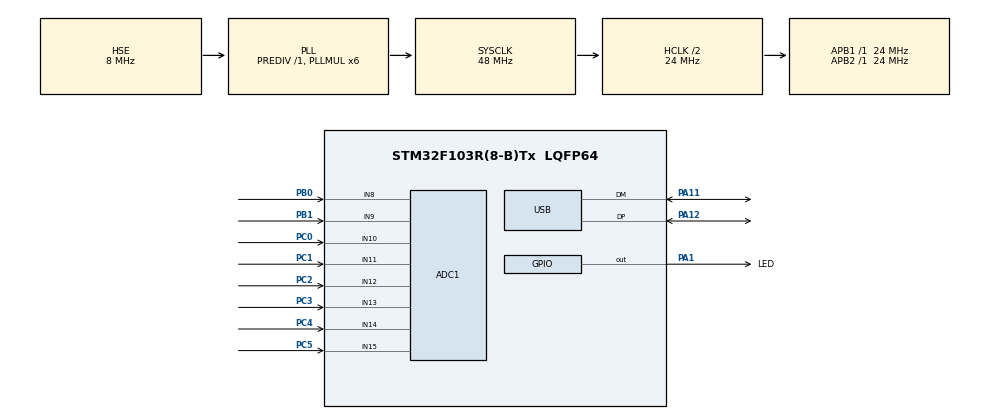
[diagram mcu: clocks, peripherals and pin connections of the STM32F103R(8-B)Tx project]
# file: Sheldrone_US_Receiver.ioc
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ADC1.Channel-0\#ChannelRegularConversion=ADC_CHANNEL_8
ADC1.Channel-1\#ChannelRegularConversion=ADC_CHANNEL_9
ADC1.Channel-2\#ChannelRegularConversion=ADC_CHANNEL_10
ADC1.Channel-3\#ChannelRegularConversion=ADC_CHANNEL_11
ADC1.Channel-4\#ChannelRegularConversion=ADC_CHANNEL_12
ADC1.Channel-5\#ChannelRegularConversion=ADC_CHANNEL_13
ADC1.Channel-6\#ChannelRegularConversion=ADC_CHANNEL_14
ADC1.Channel-7\#ChannelRegularConversion=ADC_CHANNEL_15
ADC1.ContinuousConvMode=ENABLE
ADC1.InjNumberOfConversion=0
ADC1.NbrOfConversion=8
ADC1.NbrOfConversionFlag=1
ADC1.Rank-0\#ChannelRegularConversion=1
ADC1.Rank-1\#ChannelRegularConversion=2
ADC1.Rank-2\#ChannelRegularConversion=3
ADC1.Rank-3\#ChannelRegularConversion=4
ADC1.Rank-4\#ChannelRegularConversion=5
ADC1.Rank-5\#ChannelRegularConversion=6
ADC1.Rank-6\#ChannelRegularConversion=7
ADC1.Rank-7\#ChannelRegularConversion=8
ADC1.SamplingTime-0\#ChannelRegularConversion=ADC_SAMPLETIME_1CYCLE_5
ADC1.SamplingTime-1\#ChannelRegularConversion=ADC_SAMPLETIME_1CYCLE_5
ADC1.SamplingTime-2\#ChannelRegularConversion=ADC_SAMPLETIME_1CYCLE_5
ADC1.SamplingTime-3\#ChannelRegularConversion=ADC_SAMPLETIME_1CYCLE_5
ADC1.SamplingTime-4\#ChannelRegularConversion=ADC_SAMPLETIME_1CYCLE_5
ADC1.SamplingTime-5\#ChannelRegularConversion=ADC_SAMPLETIME_1CYCLE_5
ADC1.SamplingTime-6\#ChannelRegularConversion=ADC_SAMPLETIME_1CYCLE_5
ADC1.SamplingTime-7\#ChannelRegularConversion=ADC_SAMPLETIME_1CYCLE_5
ADC1.master=1
Dma.ADC1.0.Direction=DMA_PERIPH_TO_MEMORY
Dma.ADC1.0.Instance=DMA1_Channel1
Dma.ADC1.0.MemDataAlignment=DMA_MDATAALIGN_HALFWORD
Dma.ADC1.0.MemInc=DMA_MINC_ENABLE
Dma.ADC1.0.Mode=DMA_CIRCULAR
Dma.ADC1.0.PeriphDataAlignment=DMA_PDATAALIGN_HALFWORD
Dma.ADC1.0.PeriphInc=DMA_PINC_DISABLE
Dma.ADC1.0.Priority=DMA_PRIORITY_MEDIUM
Dma.Request0=ADC1
Mcu.Family=STM32F1
Mcu.Name=STM32F103R(8-B)Tx
Mcu.Package=LQFP64
NVIC.DMA1_Channel1_IRQn=true\:0\:0\:false
NVIC.PriorityGroup=NVIC_PRIORITYGROUP_4
NVIC.USB_LP_CAN1_RX0_IRQn=true\:0\:0\:false
PA1.GPIO_Label=LED
PA1.Signal=GPIO_Output
PA11.Mode=Device
PA11.Signal=USB_DM
PA12.Mode=Device
PA12.Signal=USB_DP
PB0.Signal=ADCx_IN8
PB1.Signal=ADCx_IN9
PC0.Signal=ADCx_IN10
PC1.Signal=ADCx_IN11
PC14-OSC32_IN.Mode=LSE-External-Oscillator
PC14-OSC32_IN.Signal=RCC_OSC32_IN
PC15-OSC32_OUT.Mode=LSE-External-Oscillator
PC15-OSC32_OUT.Signal=RCC_OSC32_OUT
PC2.Signal=ADCx_IN12
PC3.Signal=ADCx_IN13
PC4.Signal=ADCx_IN14
PC5.Signal=ADCx_IN15
PD0-OSC_IN.Mode=HSE-External-Oscillator
PD0-OSC_IN.Signal=RCC_OSC_IN
PD1-OSC_OUT.Mode=HSE-External-Oscillator
PD1-OSC_OUT.Signal=RCC_OSC_OUT
ProjectManager.TargetToolchain=MDK-ARM V5
RCC.AHBCLKDivider=RCC_SYSCLK_DIV2
RCC.AHBFreq_Value=24000000
RCC.APB1Freq_Value=24000000
RCC.APB1TimFreq_Value=24000000
RCC.APB2Freq_Value=24000000
RCC.APB2TimFreq_Value=24000000
RCC.HCLKFreq_Value=24000000
RCC.HSIState=RCC_HSI_ON
RCC.PLLMUL=RCC_PLL_MUL6
RCC.SYSCLKFreq_VALUE=48000000
RCC.SYSCLKSource=RCC_SYSCLKSOURCE_PLLCLK
RCC.USBFreq_Value=48000000
SH.ADCx_IN10.0=ADC1_IN10,IN10
SH.ADCx_IN11.0=ADC1_IN11,IN11
SH.ADCx_IN12.0=ADC1_IN12,IN12
SH.ADCx_IN13.0=ADC1_IN13,IN13
SH.ADCx_IN14.0=ADC1_IN14,IN14
SH.ADCx_IN15.0=ADC1_IN15,IN15
SH.ADCx_IN8.0=ADC1_IN8,IN8
SH.ADCx_IN9.0=ADC1_IN9,IN9
USB_DEVICE.USBD_HandleTypeDef=hUsbDeviceFS
USB_DEVICE.VirtualMode=Cdc
USB_DEVICE.VirtualModeFS=Cdc_FS
VP_USB_DEVICE_VS_USB_DEVICE_CDC_FS.Mode=CDC_FS
board=Sheldrone_US_Receiver

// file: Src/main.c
/**
  ******************************************************************************
  * File Name          : main.c
  * Description        : Main program body
  ******************************************************************************
  *
  * COPYRIGHT(c) 2015 STMicroelectronics
  *
  * Redistribution and use in source and binary forms, with or without modification,
  * are permitted provided that the following conditions are met:
  *   1. Redistributions of source code must retain the above copyright notice,
  *      this list of conditions and the following disclaimer.
  *   2. Redistributions in binary form must reproduce the above copyright notice,
  *      this list of conditions and the following disclaimer in the documentation
  *      and/or other materials provided with the distribution.
  *   3. Neither the name of STMicroelectronics nor the names of its contributors
  *      may be used to endorse or promote products derived from this software
  *      without specific prior written permission.
  *
  * THIS SOFTWARE IS PROVIDED BY THE COPYRIGHT HOLDERS AND CONTRIBUTORS "AS IS"
  * AND ANY EXPRESS OR IMPLIED WARRANTIES, INCLUDING, BUT NOT LIMITED TO, THE
  * IMPLIED WARRANTIES OF MERCHANTABILITY AND FITNESS FOR A PARTICULAR PURPOSE ARE
  * DISCLAIMED. IN NO EVENT SHALL THE COPYRIGHT HOLDER OR CONTRIBUTORS BE LIABLE
  * FOR ANY DIRECT, INDIRECT, INCIDENTAL, SPECIAL, EXEMPLARY, OR CONSEQUENTIAL
  * DAMAGES (INCLUDING, BUT NOT LIMITED TO, PROCUREMENT OF SUBSTITUTE GOODS OR
  * SERVICES; LOSS OF USE, DATA, OR PROFITS; OR BUSINESS INTERRUPTION) HOWEVER
  * CAUSED AND ON ANY THEORY OF LIABILITY, WHETHER IN CONTRACT, STRICT LIABILITY,
  * OR TORT (INCLUDING NEGLIGENCE OR OTHERWISE) ARISING IN ANY WAY OUT OF THE USE
  * OF THIS SOFTWARE, EVEN IF ADVISED OF THE POSSIBILITY OF SUCH DAMAGE.
  *
  ******************************************************************************
  */
#include "stm32f1xx_hal.h"
#include "usb_device.h"
#include "usbd_cdc_if.h"

/* USER CODE BEGIN Includes */
#include "customUtils.h"
/* USER CODE END Includes */

ADC_HandleTypeDef hadc1;
DMA_HandleTypeDef hdma_adc1;

/* USER CODE BEGIN PV */
/* Private variables ---------------------------------------------------------*/

/* USER CODE END PV */

void SystemClock_Config(void);
static void MX_GPIO_Init(void);
static void MX_DMA_Init(void);
static void MX_ADC1_Init(void);

/* USER CODE BEGIN PFP */
/* Private function prototypes -----------------------------------------------*/

/* USER CODE END PFP */

/* USER CODE BEGIN 0 */

/// Array to store ADC data
#define ADC1_DATA_ARRAY_SIZE	1024
uint32_t ADC1ConvertedValues[ADC1_DATA_ARRAY_SIZE];

/* USER CODE END 0 */

int main(void)
{

  /* MCU Configuration----------------------------------------------------------*/

  /* Reset of all peripherals, Initializes the Flash interface and the Systick. */
  HAL_Init();

  /* Configure the system clock */
  SystemClock_Config();

  /* Initialize all configured peripherals */
  MX_GPIO_Init();
  MX_DMA_Init();
  MX_ADC1_Init();
  MX_USB_DEVICE_Init();

  /* USER CODE BEGIN 2 */

	// -- Enables ADC and starts conversion of the regular channels.
  if( HAL_ADC_Start(&hadc1) != HAL_OK)
		return 0;
  // -- Enables ADC DMA request
  if (HAL_ADC_Start_DMA(&hadc1, (uint32_t*)ADC1ConvertedValues, ADC1_DATA_ARRAY_SIZE*2) != HAL_OK)
		return 0;

  /* USER CODE END 2 */

  /* Infinite loop */
  /* USER CODE BEGIN WHILE */

	uint8_t dataToSend[11] = "Hello World";

	// Wait for USB to be ready
	//while(!Is_CDC_Ready());
	//HAL_Delay(1000);

  while (1)
  {
		//CDC_Transmit_FS(dataToSend, 11); // Length < APP_TX_DATA_SIZE
		//HAL_Delay(1000);

  /* USER CODE END WHILE */

  }

}

/** System Clock Configuration
*/
void SystemClock_Config(void)
{

  RCC_OscInitTypeDef RCC_OscInitStruct;
  RCC_ClkInitTypeDef RCC_ClkInitStruct;
  RCC_PeriphCLKInitTypeDef PeriphClkInit;

  RCC_OscInitStruct.OscillatorType = RCC_OSCILLATORTYPE_HSE;
  RCC_OscInitStruct.HSEState = RCC_HSE_ON;
  RCC_OscInitStruct.HSEPredivValue = RCC_HSE_PREDIV_DIV1;
  RCC_OscInitStruct.PLL.PLLState = RCC_PLL_ON;
  RCC_OscInitStruct.PLL.PLLSource = RCC_PLLSOURCE_HSE;
  RCC_OscInitStruct.PLL.PLLMUL = RCC_PLL_MUL6;
  HAL_RCC_OscConfig(&RCC_OscInitStruct);

  RCC_ClkInitStruct.ClockType = RCC_CLOCKTYPE_HCLK|RCC_CLOCKTYPE_SYSCLK;
  RCC_ClkInitStruct.SYSCLKSource = RCC_SYSCLKSOURCE_PLLCLK;
  RCC_ClkInitStruct.AHBCLKDivider = RCC_SYSCLK_DIV2;
  RCC_ClkInitStruct.APB1CLKDivider = RCC_HCLK_DIV1;
  RCC_ClkInitStruct.APB2CLKDivider = RCC_HCLK_DIV1;
  HAL_RCC_ClockConfig(&RCC_ClkInitStruct, FLASH_LATENCY_0);

  PeriphClkInit.PeriphClockSelection = RCC_PERIPHCLK_ADC|RCC_PERIPHCLK_USB;
  PeriphClkInit.AdcClockSelection = RCC_ADCPCLK2_DIV2;
  PeriphClkInit.UsbClockSelection = RCC_USBPLLCLK_DIV1;
  HAL_RCCEx_PeriphCLKConfig(&PeriphClkInit);

  HAL_SYSTICK_Config(HAL_RCC_GetHCLKFreq()/1000);

  HAL_SYSTICK_CLKSourceConfig(SYSTICK_CLKSOURCE_HCLK);

  /* SysTick_IRQn interrupt configuration */
  HAL_NVIC_SetPriority(SysTick_IRQn, 0, 0);
}

/* ADC1 init function */
void MX_ADC1_Init(void)
{

  ADC_ChannelConfTypeDef sConfig;

    /**Common config
    */
  hadc1.Instance = ADC1;
  hadc1.Init.ScanConvMode = ADC_SCAN_ENABLE;
  hadc1.Init.ContinuousConvMode = ENABLE;
  hadc1.Init.DiscontinuousConvMode = DISABLE;
  hadc1.Init.ExternalTrigConv = ADC_SOFTWARE_START;
  hadc1.Init.DataAlign = ADC_DATAALIGN_RIGHT;
  hadc1.Init.NbrOfConversion = 8;
  HAL_ADC_Init(&hadc1);

    /**Configure Regular Channel
    */
  sConfig.Channel = ADC_CHANNEL_8;
  sConfig.Rank = 1;
  sConfig.SamplingTime = ADC_SAMPLETIME_1CYCLE_5;
  HAL_ADC_ConfigChannel(&hadc1, &sConfig);

    /**Configure Regular Channel
    */
  sConfig.Channel = ADC_CHANNEL_9;
  sConfig.Rank = 2;
  HAL_ADC_ConfigChannel(&hadc1, &sConfig);

    /**Configure Regular Channel
    */
  sConfig.Channel = ADC_CHANNEL_10;
  sConfig.Rank = 3;
  HAL_ADC_ConfigChannel(&hadc1, &sConfig);

    /**Configure Regular Channel
    */
  sConfig.Channel = ADC_CHANNEL_11;
  sConfig.Rank = 4;
  HAL_ADC_ConfigChannel(&hadc1, &sConfig);

    /**Configure Regular Channel
    */
  sConfig.Channel = ADC_CHANNEL_12;
  sConfig.Rank = 5;
  HAL_ADC_ConfigChannel(&hadc1, &sConfig);

    /**Configure Regular Channel
    */
  sConfig.Channel = ADC_CHANNEL_13;
  sConfig.Rank = 6;
  HAL_ADC_ConfigChannel(&hadc1, &sConfig);

    /**Configure Regular Channel
    */
  sConfig.Channel = ADC_CHANNEL_14;
  sConfig.Rank = 7;
  HAL_ADC_ConfigChannel(&hadc1, &sConfig);

    /**Configure Regular Channel
    */
  sConfig.Channel = ADC_CHANNEL_15;
  sConfig.Rank = 8;
  HAL_ADC_ConfigChannel(&hadc1, &sConfig);

}

void MX_DMA_Init(void)
{
  /* DMA controller clock enable */
  __HAL_RCC_DMA1_CLK_ENABLE();

  /* DMA interrupt init */
  HAL_NVIC_SetPriority(DMA1_Channel1_IRQn, 0, 0);
  HAL_NVIC_EnableIRQ(DMA1_Channel1_IRQn);

}

/** Configure pins as
        * Analog
        * Input
        * Output
        * EVENT_OUT
        * EXTI
*/
void MX_GPIO_Init(void)
{

  GPIO_InitTypeDef GPIO_InitStruct;

  /* GPIO Ports Clock Enable */
  __GPIOC_CLK_ENABLE();
  __GPIOD_CLK_ENABLE();
  __GPIOA_CLK_ENABLE();
  __GPIOB_CLK_ENABLE();

  /*Configure GPIO pin : LED_Pin */
  GPIO_InitStruct.Pin = LED_Pin;
  GPIO_InitStruct.Mode = GPIO_MODE_OUTPUT_PP;
  GPIO_InitStruct.Speed = GPIO_SPEED_LOW;
  HAL_GPIO_Init(LED_GPIO_Port, &GPIO_InitStruct);

}

/************************ (C) COPYRIGHT STMicroelectronics *****END OF FILE****/
